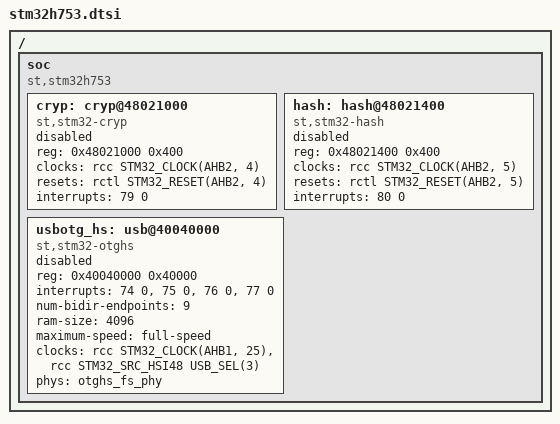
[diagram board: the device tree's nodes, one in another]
/*
 * Copyright (c) 2020 Petri Oksanen <petri@iote.ai>
 *
 * SPDX-License-Identifier: Apache-2.0
 */

#include <st/h7/stm32h743.dtsi>

/ {
	soc {
		compatible = "st,stm32h753", "st,stm32h7", "simple-bus";

		cryp: cryp@48021000 {
			compatible = "st,stm32-cryp";
			reg = <0x48021000 0x400>;
			clocks = <&rcc STM32_CLOCK(AHB2, 4)>;
			resets = <&rctl STM32_RESET(AHB2, 4)>;
			interrupts = <79 0>;
			status = "disabled";
		};

		hash: hash@48021400 {
			compatible = "st,stm32-hash";
			reg = <0x48021400 0x400>;
			clocks = <&rcc STM32_CLOCK(AHB2, 5)>;
			resets = <&rctl STM32_RESET(AHB2, 5)>;
			interrupts = <80 0>;
			status = "disabled";
		};

		usbotg_hs: usb@40040000 {
			compatible = "st,stm32-otghs";
			reg = <0x40040000 0x40000>;
			interrupts = <74 0>, <75 0>, <76 0>, <77 0>;
			interrupt-names = "ep1_out", "ep1_in", "wkup", "otghs";
			num-bidir-endpoints = <9>;
			ram-size = <4096>;
			maximum-speed = "full-speed";
			clocks = <&rcc STM32_CLOCK(AHB1, 25)>,
				 <&rcc STM32_SRC_HSI48 USB_SEL(3)>;
			phys = <&otghs_fs_phy>;
			status = "disabled";
		};
	};
};
